# tviic2d6mddr register map
Vendor: Cypress Semiconductor; Series: tviic2d6mddr; File version: 1.0
CPU: CM7 r0p1, little endian, MPU, FPU, VTOR, 3 interrupt priority bits
Registers are 32-bit, read-write, reset 0x0 unless marked. A register's access mark holds for its fields unless they carry their own. Offsets are from the block's base; [hi:lo] are bit positions; lines under a group give offsets from that group; {n}, {i} and the like mark numbered series; 'fields as' and 'values as' point back to an identical list.

## VIDEOSS0 (part 12 of 18) — Video and Graphics Subsystem IP
Base 0x40A00000
0x80000 VIDEOIO group — Video I/O Core
  0x20000 DISENG0 group — Display Engine
    0x3000 TCON0 group — Timing Controller
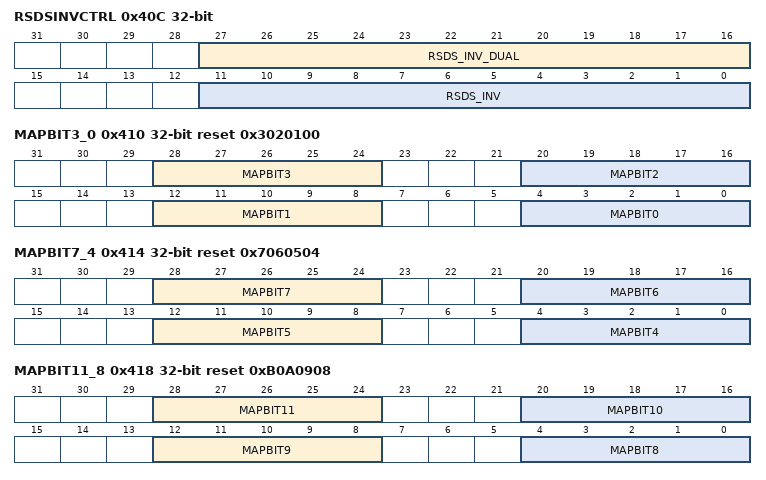
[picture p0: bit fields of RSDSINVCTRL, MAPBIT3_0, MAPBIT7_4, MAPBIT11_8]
      0x40C RSDSINVCTRL — Controls inversion of output polarity when connected IO cells operate in RSDS mode
        [27:16] RSDS_INV_DUAL — Same as RSDS_inv for 2nd channel
        [11:0] RSDS_INV — Inversion vector for 1st channel. For i in [ 0 .. 11 ]; if RSDS_Inv [ i ] == 0 => NON-Inversion of RSDS [ i ] else Inversion of RSDS [ i ]
      0x410 MAPBIT3_0 reset 0x3020100 — Mapping of 24 bit RGB or Timing Generator TSig[5-0] to bit 0 .. 3
        [28:24] MAPBIT3 — map bit[ 3 ] from [ Blue, Green, Red ] or from TSig[5-0]. If MapBit3 in [ 23..0 ] => bit[ 3 ] = [ Blue, Green, Red ] [ MapBit3 ]; if MapBit3 in [29 .. 24] => bit[ 3 ] in { TSig[5] .. TSig[0] }; If MapBit3 = 31 => bit[ 3 ] = 0 ; if MapBit3= 30 => bit[ 3 ] = 1
        [20:16] MAPBIT2 — map bit[ 2 ] from [ Blue, Green, Red ] or from TSig[5-0]. If MapBit2 in [ 23..0 ] => bit[ 2 ] = [ Blue, Green, Red ] [ MapBit2 ]; if MapBit2 in [29 .. 24] => bit[ 2 ] in { TSig[5] .. TSig[0] }; If MapBit2 = 31 => bit[ 2 ] = 0 ; if MapBit2= 30 => bit[ 2 ] = 1
        [12:8] MAPBIT1 — map bit[ 1 ] from [ Blue, Green, Red ] or from TSig[5-0]. If MapBit1 in [ 23..0 ] => bit[ 1 ] = [ Blue, Green, Red ] [ MapBit1 ]; if MapBit1 in [29 .. 24] => bit[ 1 ] in { TSig[5] .. TSig[0] }; If MapBit1 = 31 => bit[ 1 ] = 0 ; if MapBit1= 30 => bit[ 1 ] = 1
        [4:0] MAPBIT0 — map bit[ 0 ] from [ Blue, Green, Red ] or from TSig[5-0]. If MapBit0 in [ 23..0 ] => bit[ 0 ] = [ Blue, Green, Red ] [ MapBit0 ]; if MapBit0 in [29 .. 24] => bit[ 0 ] in { TSig[5] .. TSig[0] }; If MapBit0 = 31 => bit[ 0 ] = 0 ; if MapBit1= 30 => bit[ 0 ] = 1
      0x414 MAPBIT7_4 reset 0x7060504 — Mapping of 24 bit RGB or Timing Generator TSig[5-0] to bit 4 .. 7
        [28:24] MAPBIT7 — map bit[ 7 ] from [ Blue, Green, Red ] or from TSig[5-0]. If MapBit7 in [ 23..0 ] => bit[ 7 ] = [ Blue, Green, Red ] [ MapBit7 ]; if MapBit7 in [29 .. 24] => bit[ 7 ] in { TSig[5] .. TSig[0] }; If MapBit7 = 31 => bit[ 7 ] = 0 ; if MapBit7= 30 => bit[ 7 ] = 1
        [20:16] MAPBIT6 — map bit[ 6 ] from [ Blue, Green, Red ] or from TSig[5-0]. If MapBit6 in [ 23..0 ] => bit[ 6 ] = [ Blue, Green, Red ] [ MapBit6 ]; if MapBit6 in [29 .. 24] => bit[ 6 ] in { TSig[5] .. TSig[0] }; If MapBit6 = 31 => bit[ 6 ] = 0 ; if MapBit6= 30 => bit[ 6 ] = 1
        [12:8] MAPBIT5 — map bit[ 5 ] from [ Blue, Green, Red ] or from TSig[5-0]. If MapBit5 in [ 23..0 ] => bit[ 5 ] = [ Blue, Green, Red ] [ MapBit5 ]; if MapBit5 in [29 .. 24] => bit[ 5 ] in { TSig[5] .. TSig[0] }; If MapBit5 = 31 => bit[ 5 ] = 0 ; if MapBit5= 30 => bit[ 5 ] = 1
        [4:0] MAPBIT4 — map bit[ 4 ] from [ Blue, Green, Red ] or from TSig[5-0]. If MapBit4 in [ 23..0 ] => bit[ 4 ] = [ Blue, Green, Red ] [ MapBit4 ]; if MapBit4 in [29 .. 24] => bit[ 4 ] in { TSig[5] .. TSig[0] }; If MapBit4 = 31 => bit[ 4 ] = 0 ; if MapBit4= 30 => bit[ 4 ] = 1
      0x418 MAPBIT11_8 reset 0xB0A0908 — Mapping of 24 bit RGB or Timing Generator TSig[5-0] to bit 8 .. 11
        [28:24] MAPBIT11 — map bit[ 11 ] from [ Blue, Green, Red ] or from TSig[5-0]. If MapBit11 in [ 23..0 ] => bit[ 11 ] = [ Blue, Green, Red ] [ MapBit11 ]; if MapBit11 in [29 .. 24] => bit[ 11 ] in { TSig[5] .. TSig[0] } ; If MapBit11 = 31 => bit[ 11 ] = 0 ; if MapBit11= 30 => bit[ 11 ] = 1
        [20:16] MAPBIT10 — map bit[ 10 ] from [ Blue, Green, Red ] or from TSig[5-0]. If MapBit10 in [ 23..0 ] => bit[ 10 ] = [ Blue, Green, Red ] [ MapBit10 ]; if MapBit10 in [29 .. 24] => bit[ 10 ] in { TSig[5] .. TSig[0] } ; If MapBit10 = 31 => bit[ 10 ] = 0 ; if MapBit10= 30 => bit[ 10 ] = 1
        [12:8] MAPBIT9 — map bit[ 9 ] from [ Blue, Green, Red ] or from TSig[5-0]. if MapBit9 in [ 23..0 ] => bit[ 9 ] = [ Blue, Green, Red ] [ MapBit9 ]; if MapBit9 in [29 .. 24] => bit[ 9 ] in { TSig[5] .. TSig[0] }; If MapBit9 = 31 => bit[ 9 ] = 0 ; if MapBit9= 30 => bit[ 9 ] = 1
        [4:0] MAPBIT8 — map bit[ 8 ] from [ Blue, Green, Red ] or from TSig[5-0]. if MapBit8 in [ 23..0 ] => bit[ 8 ] = [ Blue, Green, Red ] [ MapBit8 ]; if MapBit8 in [29 .. 24] => bit[ 8 ] in { TSig[5] .. TSig[0] }; If MapBit8 = 31 => bit[ 8 ] = 0 ; if MapBit8= 30 => bit[ 8 ] = 1
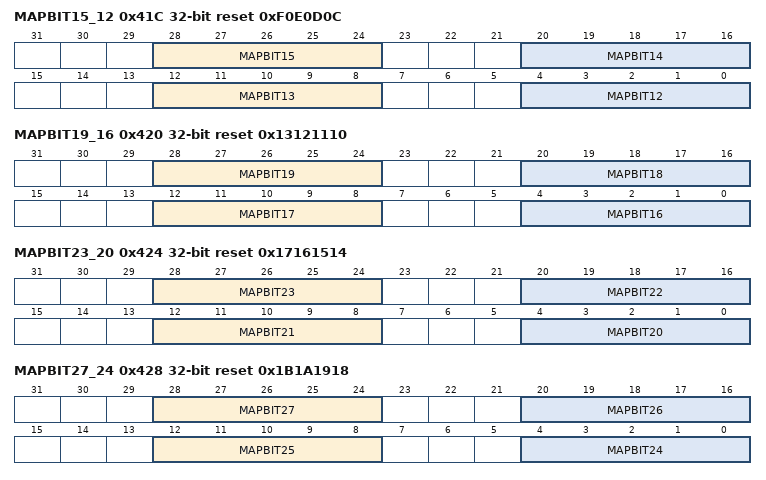
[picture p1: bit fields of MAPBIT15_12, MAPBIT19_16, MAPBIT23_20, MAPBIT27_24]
      0x41C MAPBIT15_12 reset 0xF0E0D0C — Mapping of 24 bit RGB or Timing Generator TSig[5-0] to bit 12 .. 15
        [28:24] MAPBIT15 — map bit[ 15 ] from [ Blue, Green, Red ] or from TSig[5-0]. If MapBit15 in [ 23..0 ] => bit[ 15 ] = [ Blue, Green, Red ] [ MapBit15 ]; if MapBit15 in [29 .. 24] => bit[ 15 ] in { TSig[5] .. TSig[0] } ; If MapBit15 = 31 => bit[ 15 ] = 0 ; if MapBit15= 30 => bit[ 15 ] = 1
        [20:16] MAPBIT14 — map bit[ 14 ] from [ Blue, Green, Red ] or from TSig[5-0]. If MapBit14 in [ 23..0 ] => bit[ 14 ] = [ Blue, Green, Red ] [ MapBit14 ]; if MapBit14 in [29 .. 24] => bit[ 14 ] in { TSig[5] .. TSig[0] } ; If MapBit14 = 31 => bit[ 14 ] = 0 ; if MapBit14= 30 => bit[ 14 ] = 1
        [12:8] MAPBIT13 — map bit[ 13 ] from [ Blue, Green, Red ] or from TSig[5-0]. If MapBit13 in [ 23..0 ] => bit[ 13 ] = [ Blue, Green, Red ] [ MapBit13 ]; if MapBit13 in [29 .. 24] => bit[ 13 ] in { TSig[5] .. TSig[0] } ; If MapBit13 = 31 => bit[ 13 ] = 0 ; if MapBit13= 30 => bit[ 13 ] = 1
        [4:0] MAPBIT12 — map bit[ 12 ] from [ Blue, Green, Red ] or from TSig[5-0]. If MapBit12 in [ 23..0 ] => bit[ 12 ] = [ Blue, Green, Red ] [ MapBit12 ]; if MapBit12 in [29 .. 24] => bit[ 12 ] in { TSig[5] .. TSig[0] } ; If MapBit12 = 31 => bit[ 12 ] = 0 ; if MapBit12= 30 => bit[ 12 ] = 1
      0x420 MAPBIT19_16 reset 0x13121110 — Mapping of 24 bit RGB or Timing Generator TSig[5-0] to bit 16 .. 19
        [28:24] MAPBIT19 — map bit[ 19 ] from [ Blue, Green, Red ] or from TSig[5-0]. If MapBit19 in [ 23..0 ] => bit[ 19 ] = [ Blue, Green, Red ] [ MapBit19 ]; if MapBit19 in [29 .. 24] => bit[ 19 ] in { TSig[5] .. TSig[0] } ; If MapBit19 = 31 => bit[ 19 ] = 0 ; if MapBit19= 30 => bit[ 19 ] = 1
        [20:16] MAPBIT18 — map bit[ 18 ] from [ Blue, Green, Red ] or from TSig[5-0]. If MapBit18 in [ 23..0 ] => bit[ 18 ] = [ Blue, Green, Red ] [ MapBit18 ]; if MapBit18 in [29 .. 24] => bit[ 18 ] in { TSig[5] .. TSig[0] } ; If MapBit18 = 31 => bit[ 18 ] = 0 ; if MapBit18= 30 => bit[ 18 ] = 1
        [12:8] MAPBIT17 — map bit[ 17 ] from [ Blue, Green, Red ] or from TSig[5-0]. If MapBit17 in [ 23..0 ] => bit[ 17 ] = [ Blue, Green, Red ] [ MapBit17 ]; if MapBit17 in [29 .. 24] => bit[ 17 ] in { TSig[5] .. TSig[0] } ; If MapBit17 = 31 => bit[ 17 ] = 0 ; if MapBit17= 30 => bit[ 17 ] = 1
        [4:0] MAPBIT16 — map bit[ 16 ] from [ Blue, Green, Red ] or from TSig[5-0]. If MapBit16 in [ 23..0 ] => bit[ 16 ] = [ Blue, Green, Red ] [ MapBit16 ]; if MapBit16 in [29 .. 24] => bit[ 16 ] in { TSig[5] .. TSig[0] } ; If MapBit16 = 31 => bit[ 16 ] = 0 ; if MapBit16= 30 => bit[ 16 ] = 1
      0x424 MAPBIT23_20 reset 0x17161514 — Mapping of 24 bit RGB or Timing Generator TSig[5-0] to bit 20 .. 23
        [28:24] MAPBIT23 — map bit[ 23 ] from [ Blue, Green, Red ] or from TSig[5-0]. If MapBit23 in [ 23..0 ] => bit[ 23 ] = [ Blue, Green, Red ] [ MapBit23 ]; if MapBit23 in [29 .. 24] => bit[ 23 ] in { TSig[5] .. TSig[0] } ; If MapBit23 = 31 => bit[ 23 ] = 0 ; if MapBit23= 30 => bit[ 23 ] = 1
        [20:16] MAPBIT22 — map bit[ 22 ] from [ Blue, Green, Red ] or from TSig[5-0]. If MapBit22 in [ 23..0 ] => bit[ 22 ] = [ Blue, Green, Red ] [ MapBit22 ]; if MapBit22 in [29 .. 24] => bit[ 22 ] in { TSig[5] .. TSig[0] } ; If MapBit22 = 31 => bit[ 22 ] = 0 ; if MapBit22= 30 => bit[ 22 ] = 1
        [12:8] MAPBIT21 — map bit[ 21 ] from [ Blue, Green, Red ] or from TSig[5-0]. If MapBit21 in [ 23..0 ] => bit[ 21 ] = [ Blue, Green, Red ] [ MapBit21 ]; if MapBit21 in [29 .. 24] => bit[ 21 ] in { TSig[5] .. TSig[0] } ; If MapBit21 = 31 => bit[ 21 ] = 0 ; if MapBit21= 30 => bit[ 21 ] = 1
        [4:0] MAPBIT20 — map bit[ 20 ] from [ Blue, Green, Red ] or from TSig[5-0]. If MapBit20 in [ 23..0 ] => bit[ 20 ] = [ Blue, Green, Red ] [ MapBit20 ]; if MapBit20 in [29 .. 24] => bit[ 20 ] in { TSig[5] .. TSig[0] } ; If MapBit20 = 31 => bit[ 20 ] = 0 ; if MapBit20= 30 => bit[ 20 ] = 1
      0x428 MAPBIT27_24 reset 0x1B1A1918 — Mapping of 24 bit RGB or Timing Generator TSig[5-0] to bit 24 .. 27
        [28:24] MAPBIT27 — map bit[27] from [ Blue, Green, Red ] or from TSig[5-0]. If MapBit27 in [ 23..0 ] => bit[27] = [ Blue, Green, Red ] [ MapBit27 ]; if MapBit27 in [29 .. 24] => bit[27] in { TSig[5] .. TSig[0] } ; If MapBit27 = 31 => bit[27] = 0 ; if MapBit27= 30 => bit[27] = 1
        [20:16] MAPBIT26 — map bit[26] from [ Blue, Green, Red ] or from TSig[5-0]. If MapBit26 in [ 23..0 ] => bit[26] = [ Blue, Green, Red ] [ MapBit26 ]; if MapBit26 in [29 .. 24] => bit[26] in { TSig[5] .. TSig[0] } ; If MapBit26 = 31 => bit[26] = 0 ; if MapBit26= 30 => bit[26] = 1
        [12:8] MAPBIT25 — map bit[25] from [ Blue, Green, Red ] or from TSig[5-0]. If MapBit25 in [ 23..0 ] => bit[25] = [ Blue, Green, Red ] [ MapBit25 ]; if MapBit25 in [29 .. 24] => bit[25] in { TSig[5] .. TSig[0] } ; If MapBit25 = 31 => bit[25] = 0 ; if MapBit25= 30 => bit[25] = 1
        [4:0] MAPBIT24 — map bit[24] from [ Blue, Green, Red ] or from TSig[5-0]. If MapBit24 in [ 23..0 ] => bit[24] = [ Blue, Green, Red ] [ MapBit24 ]; if MapBit24 in [29 .. 24] => bit[24] in { TSig[5] .. TSig[0] } ; If MapBit24 = 31 => bit[24] = 0 ; if MapBit24= 30 => bit[24] = 1
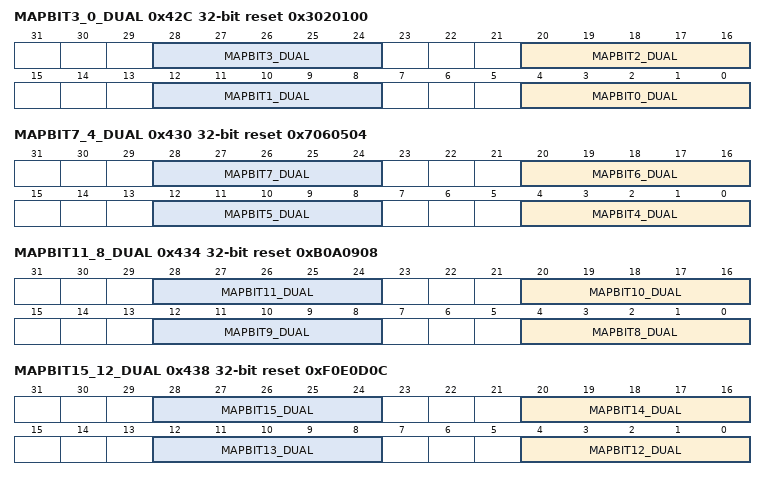
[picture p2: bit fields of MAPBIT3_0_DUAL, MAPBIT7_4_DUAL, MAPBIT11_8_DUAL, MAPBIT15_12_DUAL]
      0x42C MAPBIT3_0_DUAL reset 0x3020100 — Same as MapBit3_0 for 2nd channel
        [8n+4:8n] MAPBIT{n}_DUAL (n=0..3) — Same as MapBit{n} for 2nd channel
      0x430 MAPBIT7_4_DUAL reset 0x7060504 — Same as MapBit7_4 for 2nd channel
        [8n-28:8n-32] MAPBIT{n}_DUAL (n=4..7) — Same as MapBit{n} for 2nd channel
      0x434 MAPBIT11_8_DUAL reset 0xB0A0908 — Same as MapBit11_8 for 2nd channel
        [8n-60:8n-64] MAPBIT{n}_DUAL (n=8..11) — Same as MapBit{n} for 2nd channel
      0x438 MAPBIT15_12_DUAL reset 0xF0E0D0C — Same as MapBit15_12 for 2nd channel
        [8n-92:8n-96] MAPBIT{n}_DUAL (n=12..15) — Same as MapBit{n} for 2nd channel
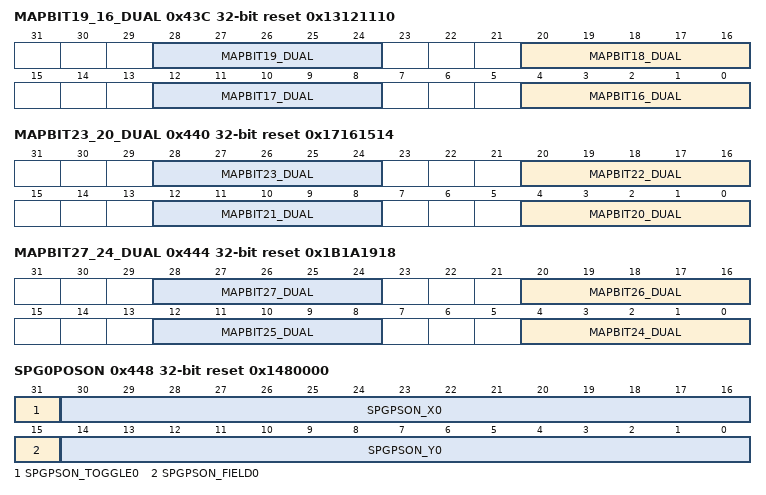
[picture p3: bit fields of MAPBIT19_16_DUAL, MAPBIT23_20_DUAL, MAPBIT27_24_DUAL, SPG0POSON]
      0x43C MAPBIT19_16_DUAL reset 0x13121110 — Same as MapBit19_16 for 2nd channel
        [8n-124:8n-128] MAPBIT{n}_DUAL (n=16..19) — Same as MapBit{n} for 2nd channel
      0x440 MAPBIT23_20_DUAL reset 0x17161514 — Same as MapBit23_20 for 2nd channel
        [8n-156:8n-160] MAPBIT{n}_DUAL (n=20..23) — Same as MapBit{n} for 2nd channel
      0x444 MAPBIT27_24_DUAL reset 0x1B1A1918 — Same as MapBit27_24 for 2nd channel
        [8n-188:8n-192] MAPBIT{n}_DUAL (n=24..27) — Same as MapBit{n} for 2nd channel
      0x448 SPG0POSON reset 0x1480000 — Sync pulse generator 0, 'Switch on' position
        [31] SPGPSON_TOGGLE0 — Toggle enable 0b=disable, 1b=enable
        [30:16] SPGPSON_X0 — X scan position
        [15] SPGPSON_FIELD0 — Field 0b=odd field, 1b=even field
        [14:0] SPGPSON_Y0 — Y scan position
      0x44C SPG0MASKON reset 0xFFFF — The Sequencer Pulse Generator 0 Mask Enable register is used to mask the enable of SPG 0
        [30:0] SPGMKON0 — Mask bits 0b=Include this bit in position matching, 1b= Do not include this bit in position matching
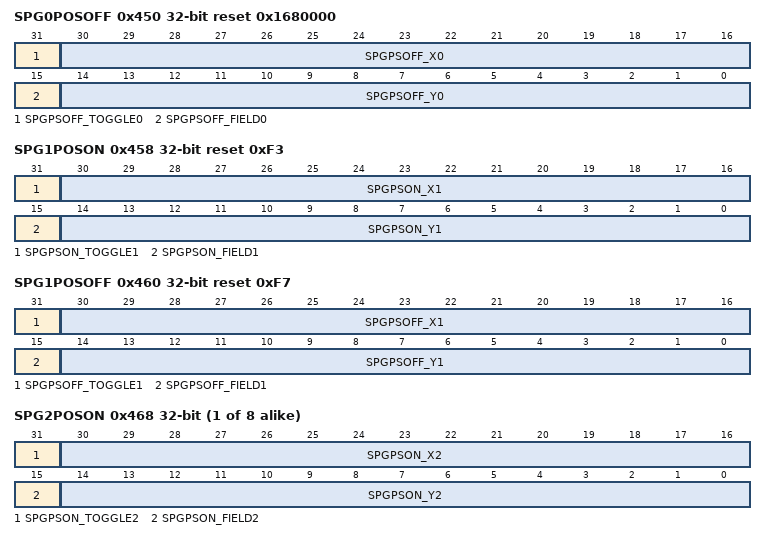
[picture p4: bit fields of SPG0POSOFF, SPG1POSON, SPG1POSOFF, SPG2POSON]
      0x450 SPG0POSOFF reset 0x1680000 — Sync pulse generator 0, 'Switch off' position
        [31] SPGPSOFF_TOGGLE0 — Toggle enable 0b=disable, 1b=enable
        [30:16] SPGPSOFF_X0 — X scan position
        [15] SPGPSOFF_FIELD0 — Field 0b=odd field, 1b=even field
        [14:0] SPGPSOFF_Y0 — Y scan position
      0x454 SPG0MASKOFF reset 0xFFFF — The Sequencer Pulse Generator 0 Mask Enable register is used to mask the disable of SPG 0
        [30:0] SPGMKOFF0 — Mask bits 0b=Include this bit in position matching, 1b= Do not include this bit in position matching
      0x458 SPG1POSON reset 0xF3 — Sync pulse generator 1, 'Switch on' position
        [31] SPGPSON_TOGGLE1 — Toggle enable 0b=disable, 1b=enable
        [30:16] SPGPSON_X1 — X scan position
        [15] SPGPSON_FIELD1 — Field 0b=odd field, 1b=even field
        [14:0] SPGPSON_Y1 — Y scan position
      0x45C SPG1MASKON reset 0x7FFF0000 — The Sequencer Pulse Generator 1 Mask Enable register is used to mask the enable of SPG 1
        [30:0] SPGMKON1 — mask bits (1= do not include this bit into position matching)
      0x460 SPG1POSOFF reset 0xF7 — Sync pulse generator 1, 'Switch off' position
        [31] SPGPSOFF_TOGGLE1 — Toggle enable 0b=disable, 1b=enable
        [30:16] SPGPSOFF_X1 — X scan position
        [15] SPGPSOFF_FIELD1 — Field 0b=odd field, 1b=even field
        [14:0] SPGPSOFF_Y1 — Y scan position
      0x464 SPG1MASKOFF reset 0x7FFF0000 — The Sequencer Pulse Generator 1 Mask Enable register is used to mask the disable of SPG 1
        [30:0] SPGMKOFF1 — Mask bits 0b=Include this bit in position matching, 1b= Do not include this bit in position matching
      {0x448+0x10*l} SPG{l}POSON (l=2..9) — Sync pulse generator {l}, 'Switch on' position
        [31] SPGPSON_TOGGLE{l} — Toggle enable 0b=disable, 1b=enable
        [30:16] SPGPSON_X{l} — X scan position
        [15] SPGPSON_FIELD{l} — Field 0b=odd field, 1b=even field
        [14:0] SPGPSON_Y{l} — Y scan position
      0x46C SPG2MASKON reset 0xFFFF — The Sequencer Pulse Generator 2 Mask Enable register is used to mask the enable of SPG 2
        [30:0] SPGMKON2 — Mask bits 0b=Include this bit in position matching, 1b= Do not include this bit in position matching
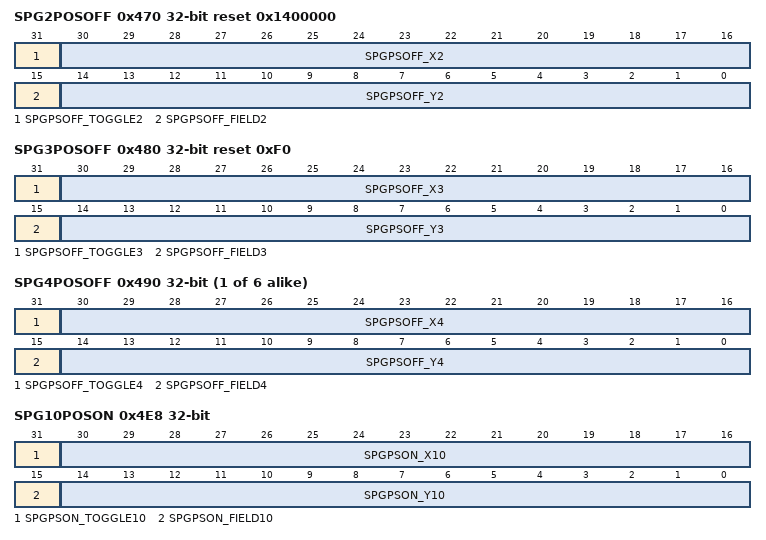
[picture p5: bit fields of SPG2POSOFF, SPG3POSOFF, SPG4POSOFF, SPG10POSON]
      0x470 SPG2POSOFF reset 0x1400000 — Sync pulse generator 2, 'Switch off' position
        [31] SPGPSOFF_TOGGLE2 — Toggle enable 0b=disable, 1b=enable
        [30:16] SPGPSOFF_X2 — X scan position
        [15] SPGPSOFF_FIELD2 — Field 0b=odd field, 1b=even field
        [14:0] SPGPSOFF_Y2 — Y scan position
      0x474 SPG2MASKOFF reset 0xFFFF — The Sequencer Pulse Generator 2 Mask Enable register is used to mask the disable of SPG 2
        [30:0] SPGMKOFF2 — Mask bits 0b=Include this bit in position matching, 1b= Do not include this bit in position matching
      0x47C SPG3MASKON reset 0x7FFF0000 — The Sequencer Pulse Generator 3 Mask Enable register is used to mask the enable of SPG 3
        [30:0] SPGMKON3 — Mask bits 0b=Include this bit in position matching, 1b= Do not include this bit in position matching
      0x480 SPG3POSOFF reset 0xF0 — Sync pulse generator 3, 'Switch off' position
        [31] SPGPSOFF_TOGGLE3 — Toggle enable 0b=disable, 1b=enable
        [30:16] SPGPSOFF_X3 — X scan position
        [15] SPGPSOFF_FIELD3 — Field 0b=odd field, 1b=even field
        [14:0] SPGPSOFF_Y3 — Y scan position
      0x484 SPG3MASKOFF reset 0x7FFF0000 — The Sequencer Pulse Generator 3 Mask Enable register is used to mask the disable of SPG 3
        [30:0] SPGMKOFF3 — Mask bits 0b=Include this bit in position matching, 1b= Do not include this bit in position matching
      {0x44C+0x10*l} SPG{l}MASKON (l=4..11) — The Sequencer Pulse Generator {l} Mask Enable register is used to mask the enable of SPG {l}
        [30:0] SPGMKON{l} — Mask bits 0b=Include this bit in position matching, 1b= Do not include this bit in position matching
      {0x450+0x10*l} SPG{l}POSOFF (l=4..9) — Sync pulse generator {l}, 'Switch off' position
        [31] SPGPSOFF_TOGGLE{l} — Toggle enable 0b=disable, 1b=enable
        [30:16] SPGPSOFF_X{l} — X scan position
        [15] SPGPSOFF_FIELD{l} — Field 0b=odd field, 1b=even field
        [14:0] SPGPSOFF_Y{l} — Y scan position
      {0x454+0x10*l} SPG{l}MASKOFF (l=4..11) — The Sequencer Pulse Generator {l} Mask Enable register is used to mask the disable of SPG {l}
        [30:0] SPGMKOFF{l} — Mask bits 0b=Include this bit in position matching, 1b= Do not include this bit in position matching
      0x4E8 SPG10POSON — Sync pulse generator 10, 'Switch on' position
        [31] SPGPSON_TOGGLE10 — toggle enable 0b=disable, 1b=enable
        [30:16] SPGPSON_X10 — X scan position
        [15] SPGPSON_FIELD10 — Field 0b=odd field, 1b=even field
        [14:0] SPGPSON_Y10 — Y scan position
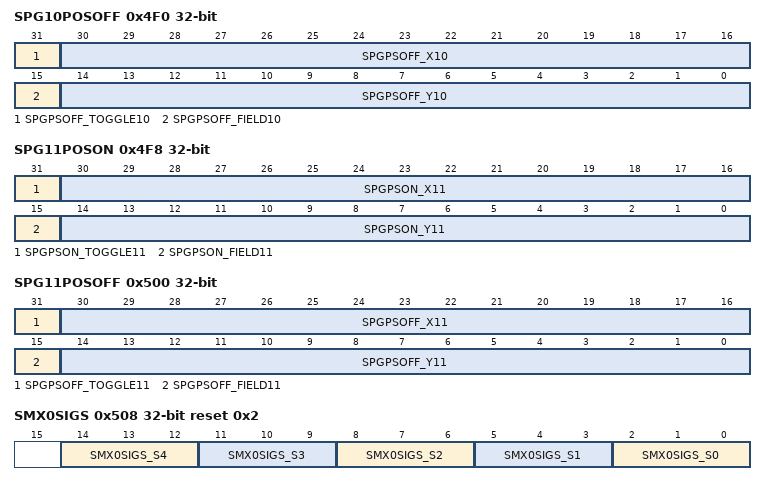
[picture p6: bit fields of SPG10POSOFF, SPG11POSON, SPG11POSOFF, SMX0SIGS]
      0x4F0 SPG10POSOFF — Sync pulse generator 10, 'Switch off' position
        [31] SPGPSOFF_TOGGLE10 — toggle enable 0b=disable, 1b=enable
        [30:16] SPGPSOFF_X10 — X scan position
        [15] SPGPSOFF_FIELD10 — Field 0b=odd field, 1b=even field
        [14:0] SPGPSOFF_Y10 — Y scan position
      0x4F8 SPG11POSON — Sync pulse generator 11, 'Switch on' position
        [31] SPGPSON_TOGGLE11 — toggle enable 0b=disable, 1b=enable
        [30:16] SPGPSON_X11 — X scan position
        [15] SPGPSON_FIELD11 — Field 0b=odd field, 1b=even field
        [14:0] SPGPSON_Y11 — Y scan position
      0x500 SPG11POSOFF — Sync pulse generator 11, 'Switch off' position
        [31] SPGPSOFF_TOGGLE11 — toggle enable 0b=disable, 1b=enable
        [30:16] SPGPSOFF_X11 — X scan position
        [15] SPGPSOFF_FIELD11 — Field 0b=odd field, 1b=even field
        [14:0] SPGPSOFF_Y11 — Y scan position
      0x508 SMX0SIGS reset 0x2 — Selection of input signals of sync mixer
        [3n+2:3n] SMX0SIGS_S{n} (n=0..4) — select {n} 000b=constant 0, 001b=sync sequencer output, 010b...111b sync pulse generator SPG0 .. SPG5
      0x50C SMX0FCTTABLE reset 0x1 — The sync mixer output is the result of the function table a=s4*2**4+s3*2**3+s2*2**2+s1*2**1+s0*2**0 whereby a is bit number and s result of sync mixer input selection
        [31:0] SMXFCT0 — Sync mixer 0 function table
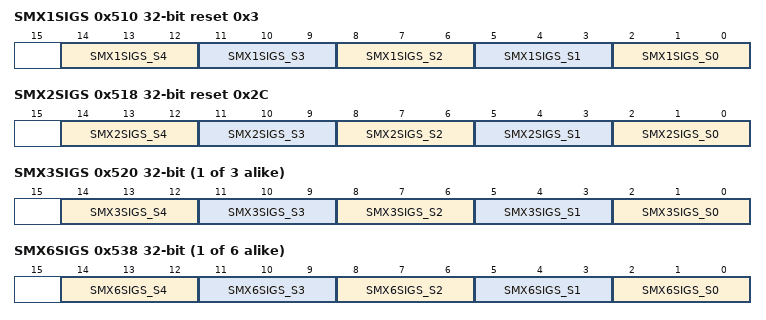
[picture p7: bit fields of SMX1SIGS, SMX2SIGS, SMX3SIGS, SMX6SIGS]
      0x510 SMX1SIGS reset 0x3 — Selection of input signals of sync mixer
        [3n+2:3n] SMX1SIGS_S{n} (n=0..4) — select {n} 000b=constant 0, 001b=sync sequencer output, 010b...111b sync pulse generator SPG0 .. SPG5
      0x514 SMX1FCTTABLE reset 0x1 — The sync mixer output is the result of the function table a=s4*2**4+s3*2**3+s2*2**2+s1*2**1+s0*2**0 whereby a is bit number and s result of sync mixer input selection
        [31:0] SMXFCT1 — Sync mixer 1 function table
      0x518 SMX2SIGS reset 0x2C — Selection of input signals of sync mixer
        [3n+2:3n] SMX2SIGS_S{n} (n=0..4) — select {n} 000b=constant 0, 001b=sync sequencer output, 010b...111b sync pulse generator SPG0 .. SPG5
      0x51C SMX2FCTTABLE reset 0x8 — The sync mixer output is the result of the function table a=s4*2**4+s**3*2**3+s2*2**2+s1*2**1+s0*2**0 whereby a is bit number and s result of sync mixer input selection
        [31:0] SMXFCT2 — Sync mixer 2 function table
      {0x508+8l} SMX{l}SIGS (l=3..5) — Selection of input signals of sync mixer
        [3n+2:3n] SMX{l}SIGS_S{n} (n=0..4) — select {n} 000b=constant 0, 001b=sync sequencer output, 010b...111b sync pulse generator SPG0 .. SPG5
      {0x50C+8l} SMX{l}FCTTABLE (l=3..11) — The sync mixer output is the result of the function table a=s4*2**4+s3*2**3+s2*2**2+s1*2**1+s0*2**0 whereby a is bit number and s result of sync mixer input selection
        [31:0] SMXFCT{l} — Sync mixer {l} function table
      {0x508+8l} SMX{l}SIGS (l=6..11) — Selection of input signals of sync mixer
        [3n+2:3n] SMX{l}SIGS_S{n} (n=0..4) — select {n} 000b=constant 0, 001b=sync sequencer output, 010b...111b sync pulse generator SPG6 .. SPG11
  0x24000 DISENG1 group — Display Engine
    0x00 DISENGCFG1 group — Top-Level Configuration
      0x00 CTL reset 0x1 — Display engine control register.
        [0] DSPCLKDIVIDE — Controls generation of display clock signals for display stream.
          0=DIV1 (External display clock signal has pixel clock frequency.); 1=DIV2 (External display clock signal has twice the pixel clock frequency.)
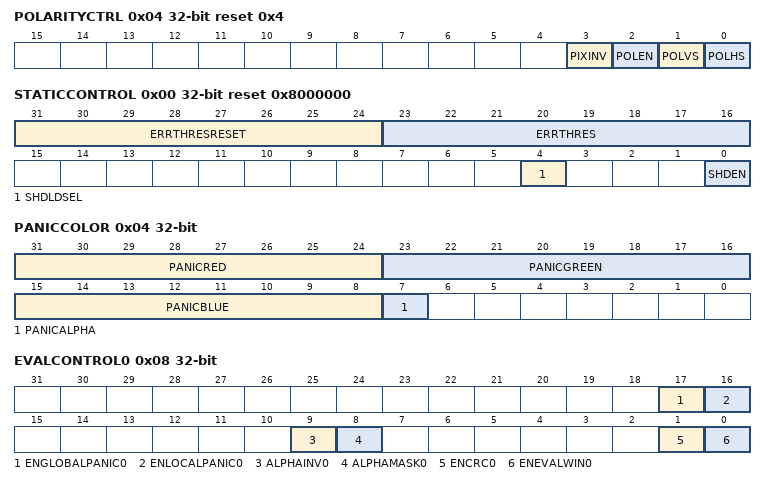
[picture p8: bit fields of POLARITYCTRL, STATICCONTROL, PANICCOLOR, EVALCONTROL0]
      0x04 POLARITYCTRL reset 0x4 — Polarity control for TCon input and corresponding top-level output (TCon by-pass port).
        [3] PIXINV — Inversion of RGB data.
          0=NONINV (No inversion of pixel data); 1=INV (Pixel data inverted (1. complement))
        [2] POLEN — Polarity of Data_Enable signal.
          0=LOW (Low active); 1=HIGH (High active)
        [1] POLVS — Polarity of vsync signal.
          0=LOW (Low active); 1=HIGH (High active)
        [0] POLHS — Polarity of hsync signal.
          0=LOW (Low active); 1=HIGH (High active)
      0x10 SIGSELECT — Tap selection for Signature.
        [1:0] SIG_SELECT — Selects a source for Sig unit.
          0=NONE (No source.); 1=FRAMEGEN (Source is FrameGen output.); 2=GAMMACOR (Source is GammaCor output.); 3=DITHER (Source is Dither output.)
      0x14 HISTOGRAMSELECT — Tap selection for Histogram.
        [1:0] HISTOGRAM_SELECT — Selects a source for Histogram unit.
          values as VIDEOIO.DISENG1.DISENGCFG1.SIGSELECT.SIG_SELECT
      0x20 DUMPSELECT — Tap selection for Frame Dump.
        [9:8] DUMP_SELECT — Selects a source for FrameDump unit.
          values as VIDEOIO.DISENG1.DISENGCFG1.SIGSELECT.SIG_SELECT
    0x1000 SIG1 group — Signature Unit
      0x00 STATICCONTROL reset 0x8000000 — Global configuration shared by all evaluation windows.
        [31:24] ERRTHRESRESET — ErrThresReset must be programmed to value less than 255. Number of consecutive frames without signature violation before StsSigError is reset for an evaluation window. 0 means that each frame without violation will reset the status. The internal counter compared against this threshold is reset with each frame that has violation.
        [23:16] ERRTHRES — Number of frames with signature violation before StsSigError is set for an evaluation window. These frames do not need to be consecutive. 0 means that each frame with violation will set the status. The internal counter compared against this threshold is reset when 'ErrThreshReset' consecutive frames without signature violation occur.
        [4] SHDLDSEL — Source select for events that will load shadow registers into the active configuration.
          0=LOCAL (Shadows are loaded at start of frame for each evaluation window for which ShdLdReq has been set.); 1=GLOBAL (Shadows of all evaluation windows are loaded synchronous to the display stream (shadow load token received on frame input port).)
        [0] SHDEN — Enables shadow registers for RWS type fields (0 = write through, 1 = shadowed).
      0x04 PANICCOLOR — Overlay color for evaluation windows in panic mode.
        [31:24] PANICRED — Red color component.
        [23:16] PANICGREEN — Green color component.
        [15:8] PANICBLUE — Blue color component.
        [7] PANICALPHA — Alpha mask bit.
      0x08 EVALCONTROL0 — Control settings for evaluation window 0.
        [17] ENGLOBALPANIC0 — When enabled (value 1) the error status of this window (StsSigError) will activate the panic mode of the display stream's Frame Generator, which can switch to another display mode in response.
        [16] ENLOCALPANIC0 — When enabled (value 1) the error status this window (StsSigError) will replace all pixels inside the window by a constant color on the display. Skip regions due to other evaluation windows on top are not modified. AlphaMask, when enabled, is not considered for this replacement.
        [9] ALPHAINV0 — When enabled (value 1) the effect of AlphaMask is inverted (pixels with alpha bit = 1 are ignored then).
        [8] ALPHAMASK0 — When enabled (value 1) pixels with alpha bit = 0 are ignored for signature computation.
        [1] ENCRC0 — When enabled (value 1) the measured signature is checked against a reference value (SigCRCRef).
        [0] ENEVALWIN0 — When enabled (value 1) a CRC signature is computed for all pixels inside this evaluation window (SigCRC). When this bit is cleared, the internal status for this window is reset (StsSigError bit and frame counters).
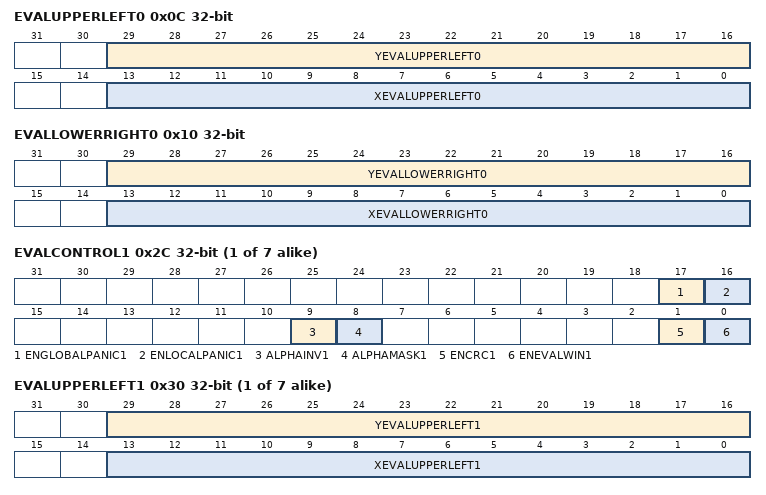
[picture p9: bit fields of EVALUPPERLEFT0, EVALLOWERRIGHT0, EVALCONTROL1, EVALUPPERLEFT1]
      0x0C EVALUPPERLEFT0 — Upper left corner of evaluation window 0.
        [29:16] YEVALUPPERLEFT0 — Y coordinate.
        [13:0] XEVALUPPERLEFT0 — X coordinate.
      0x10 EVALLOWERRIGHT0 — Lower right corner of evaluation window 0.
        [29:16] YEVALLOWERRIGHT0 — Y coordinate.
        [13:0] XEVALLOWERRIGHT0 — X coordinate.
      0x14 SIGCRCREDREF0 reset 0xFFFFFFFF — Reference signature of red channel for evaluation window 0.
        [31:0] SIGCRCREDREF0 — Reference value that is compared against measured SigCRCRed value.
      0x18 SIGCRCGREENREF0 reset 0xFFFFFFFF — Reference signature of green channel for evaluation window 0.
        [31:0] SIGCRCGREENREF0 — Reference value that is compared against measured SigCRCGreen value.
      0x1C SIGCRCBLUEREF0 reset 0xFFFFFFFF — Reference signature of blue channel for evaluation window 0.
        [31:0] SIGCRCBLUEREF0 — Reference value that is compared against measured SigCRCBlue value.
      0x20 SIGCRCRED0 ro reset 0xFFFFFFFF — Measured signature of red channel for evaluation window 0.
        [31:0] SIGCRCRED0 — CRC values from red channel.
      0x24 SIGCRCGREEN0 ro reset 0xFFFFFFFF — Measured signature of green channel for evaluation window 0.
        [31:0] SIGCRCGREEN0 — CRC values from green channel.
      0x28 SIGCRCBLUE0 ro reset 0xFFFFFFFF — Measured signature of blue channel for evaluation window 0.
        [31:0] SIGCRCBLUE0 — CRC values from blue channel.
      {0x8+0x24*l} EVALCONTROL{l} (l=1..7) — Control settings for evaluation window {l}.
        [17] ENGLOBALPANIC{l} — See EnGlobalPanic0.
        [16] ENLOCALPANIC{l} — See EnLocalPanic0.
        [9] ALPHAINV{l} — See AlphaInv0.
        [8] ALPHAMASK{l} — See AlphaMask0.
        [1] ENCRC{l} — See EnCRC0.
        [0] ENEVALWIN{l} — See EnEvalWin0.
      {0xC+0x24*l} EVALUPPERLEFT{l} (l=1..7) — Upper left corner of evaluation window {l}.
        [29:16] YEVALUPPERLEFT{l} — See YEvalUpperLeft0.
        [13:0] XEVALUPPERLEFT{l} — See XEvalUpperLeft0.
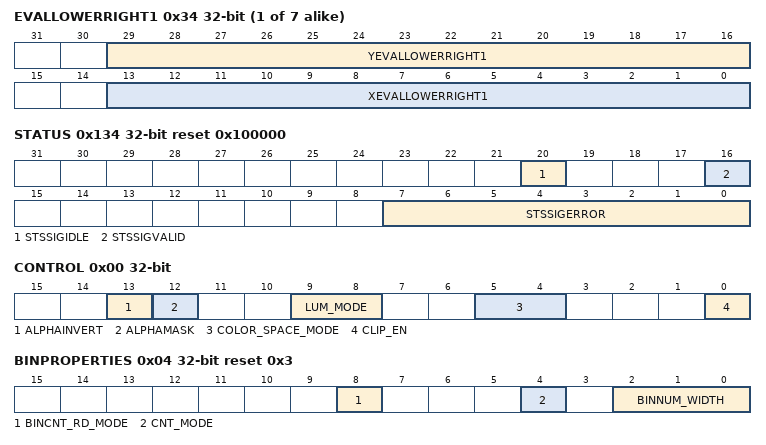
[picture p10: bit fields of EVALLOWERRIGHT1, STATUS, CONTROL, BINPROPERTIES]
      {0x10+0x24*l} EVALLOWERRIGHT{l} (l=1..7) — Lower right corner of evaluation window {l}.
        [29:16] YEVALLOWERRIGHT{l} — See YEvalLowerRight0.
        [13:0] XEVALLOWERRIGHT{l} — See XEvalLowerRight0.
      {0x14+0x24*l} SIGCRCREDREF{l} reset 0xFFFFFFFF (l=1..7) — Reference signature of red channel for evaluation window {l}.
        [31:0] SIGCRCREDREF{l} — See SigCRCRedRef0.
      {0x18+0x24*l} SIGCRCGREENREF{l} reset 0xFFFFFFFF (l=1..7) — Reference signature of green channel for evaluation window {l}.
        [31:0] SIGCRCGREENREF{l} — See SigCRCGreenRef0.
      {0x1C+0x24*l} SIGCRCBLUEREF{l} reset 0xFFFFFFFF (l=1..7) — Reference signature of blue channel for evaluation window {l}.
        [31:0] SIGCRCBLUEREF{l} — See SigCRCBlueRef0.
      {0x20+0x24*l} SIGCRCRED{l} ro reset 0xFFFFFFFF (l=1..7) — Measured signature of red channel for evaluation window {l}.
        [31:0] SIGCRCRED{l} — See SigCRCRed0.
      {0x24+0x24*l} SIGCRCGREEN{l} ro reset 0xFFFFFFFF (l=1..7) — Measured signature of green channel for evaluation window {l}.
        [31:0] SIGCRCGREEN{l} — See SigCRCGreen0.
      {0x28+0x24*l} SIGCRCBLUE{l} ro reset 0xFFFFFFFF (l=1..7) — Measured signature of blue channel for evaluation window {l}.
        [31:0] SIGCRCBLUE{l} — See SigCRCBlue0.
      0x128 SHADOWLOAD — Shadow load control register.
        [7:0] SHDLDREQ — Shadow load request for each evaluation window (bit index = window index). Writing a '1' to a bit will load the shadows into the active configuration for that window at start of next frame. Writing a '0' has no effect. The flag is reset by HW once the shadows have been loaded. A shadow load interrupt signal is generated when shadows have been loaded for at least one evaluation window. Has only effect when ShdLdSel is set to LOCAL.
      0x12C CONTINUOUSMODE — Signature operation mode control.
        [0] ENCONT — EnCont = 0: disables continuous mode. Signatures will be generated only once and in idle state after completion of measurement. In this 'ONE_TIME' mode the signature must be triggered by 'Kick' field. EnCont = 1: enables continuous mode. Write '1' to this field, signature starts and measures every incoming frame until EnCont is turned to 0. 'Kick' has no effect when 'EnCont' = 1.
      0x130 SOFTWAREKICK wo reset not defined — Signature measurement trigger.
        [0] KICK — ContinueMode.EnCont=0: Write '1' to this field in order to start signature computation with next frame. ContinueMode.EnCont=1: This field is ignored.
      0x134 STATUS ro reset 0x100000 — Module status.
        [20] STSSIGIDLE — StsSigIdle = 1: Signature is in Idle state. StsSigIdle = 0: Signature runs.
        [16] STSSIGVALID — Measured signature values are valid. This flag is set when the SigCRC fields have been updated for all enabled evaluation windows. In that case also the corresponding interrupt event is triggered. It is reset when SW writes a '1' to the 'Kick' field in order to start a new measurement.
        [7:0] STSSIGERROR — Error status bits for all evaluation windows (bit index = window index). When a bit is set it means that measured signature value is different from reference value (SigCRCRef). The bit is set when EnCRC is active and a certain number of frames have a violation (ErrThres). It is reset when the reference check for evaluation window is disabled (EnEvalWin or EnCRC) or in case a certain number of consecutive frames have no violation (ErrThresReset). The value corresponds to the panic status of this evaluation window.
    0x1400 HISTOGRAM1 group — Histogram Unit
      0x00 CONTROL — Controls some settings concerning input components and alpha mask.
        [13] ALPHAINVERT — Value 1 inverts the effect of the alpha mask mode when enabled (pixels with alpha value smaller or equal 0.5 are affecting the histogram bins).
        [12] ALPHAMASK — Value 1 enables the alpha mask mode. In this mode only pixels with an alpha value larger than 0.5 are affecting the histogram bins.
        [9:8] LUM_MODE — If a histogram for luma or luminance is required, the conversion formula for luma (Y component according to BT.601) or luminance (Y component according to BT.709) can be selected here. Luma or luminance calculation should only be applied if RGB components in range [0..255] are delivered directly at histogram input or when YCrCb components are converted to RGB by the appropriate setting of register field color_space_mode. Luma or luminance counting is delivered in first (component0) histogram. (format is unsigned integer)
          0=NO_CONV (Component0 for first histogram is counted as it is.); 1=LUMA (Component0 for first histogram is replaced by luma, which is calculated from RGB input components according to BT.601.); 2=LUMINANCE (Component0 for first histogram is replaced by luminance, which is calculated from RGB input components according to BT.709.)
        [5:4] COLOR_SPACE_MODE — Assuming that YUV(YCrCb) color components according to BT.601 or BT.709 are provided at histogram input the appropriate conversion to RGB components in [0,255] range can be selected here. (format is unsigned integer)
          0=NO_CONV (No color space conversion of input components is applied.); 1=YUV2RGB_BT601 (YUV input components as described in BT.601 are converted to RGB in [0,255] range.); 2=YUV2RGB_BT709 (YUV input components as described in BT.709 are converted to RGB in [0,255] range.)
        [0] CLIP_EN — Switch for clip window. If enabled all pixels outside the clip window are not taken into account. (format is unsigned integer)
          0=DISABLE (Clip window is switched off.); 1=ENABLE (Clip window is switched on.)
      0x04 BINPROPERTIES reset 0x3 — Configures the histogram bins.
        [8] BINCNT_RD_MODE — The field controls if the actual bin count or the sum of all bin counts up to actual bin count is provided in registers RsltComp0Bincnt, RsltComp1Bincnt and RsltComp2Bincnt. (format is unsigned integer)
          0=BINCNT (Actual bin cnt is provided.); 1=BINCNT_ACCU (Bin count sum is provided.)
        [4] CNT_MODE — Counter mode, which controls the way the bin values are accumulated. (format is unsigned integer)
          0=NEAREST (Counter of nearest bin is incremented.); 1=LINEAR (Counters of the 2 nearest bins are increased by one minus the distance to bin center (normalized between 0 and 1), it works only for first (component0) histogram, reading of component1/2 histogram results in undefined data.)
        [2:0] BINNUM_WIDTH — 2**binnum_width is the number of bins in a histogram. (format is unsigned integer)
          3=BINS_8 (There are 8 bins, addressable with 3bit.); 4=BINS_16 (There are 16 bins, addressable with 4bit.); 5=BINS_32 (There are 32 bins, addressable with 5bit.); 6=BINS_64 (There are 64 bins, addressable with 6bit.)
